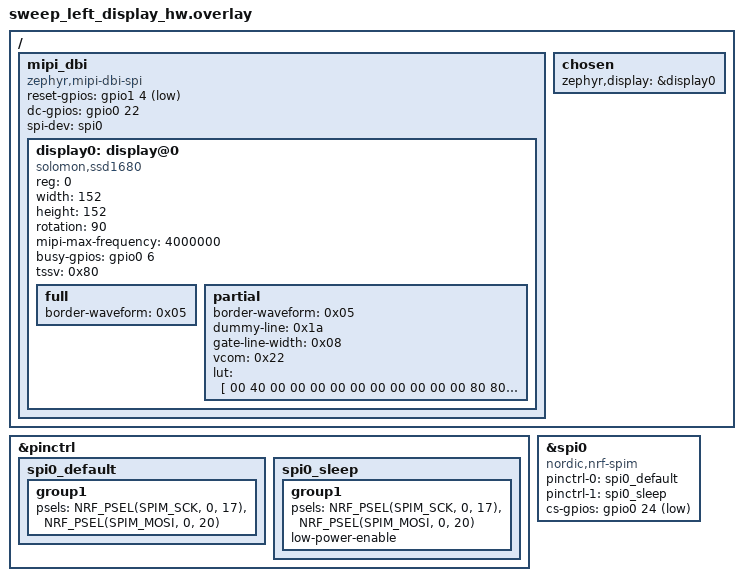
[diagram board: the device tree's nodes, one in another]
#include <zephyr/dt-bindings/mipi_dbi/mipi_dbi.h>

&pinctrl {
	spi0_default: spi0_default {
		group1 {
			psels = <NRF_PSEL(SPIM_SCK, 0, 17)>,
				<NRF_PSEL(SPIM_MOSI, 0, 20)>;
		};
	};

	spi0_sleep: spi0_sleep {
		group1 {
			psels = <NRF_PSEL(SPIM_SCK, 0, 17)>,
				<NRF_PSEL(SPIM_MOSI, 0, 20)>;
			low-power-enable;
		};
	};
};

&spi0 {
	status = "okay";
	compatible = "nordic,nrf-spim";
	pinctrl-0 = <&spi0_default>;
	pinctrl-1 = <&spi0_sleep>;
	pinctrl-names = "default", "sleep";
	cs-gpios = <&gpio0 24 GPIO_ACTIVE_LOW>;
};

/ {
	mipi_dbi {
		compatible = "zephyr,mipi-dbi-spi";
		reset-gpios = <&gpio1 4 GPIO_ACTIVE_LOW>;
		dc-gpios = <&gpio0 22 GPIO_ACTIVE_HIGH>;
		spi-dev = <&spi0>;
		status = "okay";
		#address-cells = <1>;
		#size-cells = <0>;

		display0: display@0 {
			compatible = "solomon,ssd1680";
			status = "okay";
			reg = <0>;
			width = <152>;
			height = <152>;
			rotation = <90>;

			mipi-max-frequency = <4000000>;
			busy-gpios = <&gpio0 6 GPIO_ACTIVE_HIGH>;
			tssv = <0x80>;

			full {
				border-waveform = <0x05>;
			};

			partial {
				border-waveform = <0x05>;
				dummy-line = <0x1a>;
				gate-line-width = <0x08>;
				vcom = <0x22>;
				lut = [
				/* Voltage actions, 12 bytes per row */
				00 40 00 00 00 00 00 00 00 00 00 00
				80 80 00 00 00 00 00 00 00 00 00 00
				40 40 00 00 00 00 00 00 00 00 00 00
				00 80 00 00 00 00 00 00 00 00 00 00
				00 00 00 00 00 00 00 00 00 00 00 00

				/* Timing controls, 7 bytes per row */
				0F 00 00 00 00 00 00
				01 01 00 00 00 00 00
				00 00 00 00 00 00 00
				00 00 00 00 00 00 00
				00 00 00 00 00 00 00
				00 00 00 00 00 00 00
				00 00 00 00 00 00 00
				00 00 00 00 00 00 00
				00 00 00 00 00 00 00
				00 00 00 00 00 00 00
				00 00 00 00 00 00 00
				00 00 00 00 00 00 00

				/* Voltage levels, 9 bytes */
				22 22 22 22 22 22 00 00 00
				];
			};
		};
	};

	chosen {
		zephyr,display = &display0;
	};
};
